AUTOSAR XML (schema 00044)
package /E40_Platform_System_SystemPackage/Components
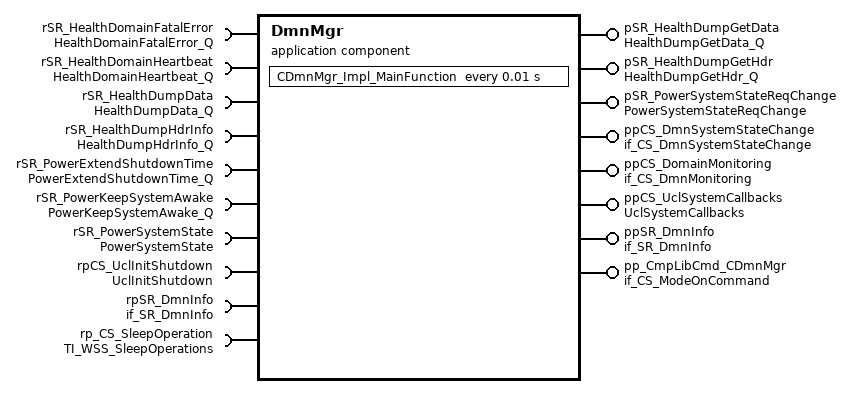
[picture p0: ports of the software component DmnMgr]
  application sw component type DmnMgr
    8 x provide port:
      pSR_HealthDumpGetData: queued-sender-com-spec=HealthDumpGetDataData, provided-interface=HealthDumpGetData_Q
      pSR_HealthDumpGetHdr: queued-sender-com-spec=HealthDumpGetHdrData, provided-interface=HealthDumpGetHdr_Q
      pSR_PowerSystemStateReqChange: nonqueued-sender-com-spec{data-element=PowerSystemStateReqChangeData, init-value=constant-reference=DmnMgrPowerSystemStateReqChangeDataValue0}, provided-interface=PowerSystemStateReqChange
      ppCS_DmnSystemStateChange: provided-interface=if_CS_DmnSystemStateChange
        provided-com-specs:
          operation=DmnSystemStateChangeReq, queue-length=1
          operation=DmnSystemStateChangeStatus, queue-length=1
      ppCS_DomainMonitoring: provided-com-specs=[{operation=StartDomainMonitoring, queue-length=1}, {operation=StopDomainMonitoring, queue-length=1}], provided-interface=if_CS_DmnMonitoring
      ppCS_UclSystemCallbacks: provided-com-specs=[{operation=ErrorNotification, queue-length=1}, {operation=LinkStatusChanged, queue-length=1}], provided-interface=UclSystemCallbacks
      ppSR_DmnInfo: nonqueued-sender-com-spec{data-element=SDmnStatus, init-value=constant-reference=DmnMgrSDmnStatusValue0}, provided-interface=if_SR_DmnInfo
      pp_CmpLibCmd_CDmnMgr: server-com-spec{operation=Impl_OnCommand, queue-length=1}, provided-interface=if_CS_ModeOnCommand
    10 x require port:
      rSR_HealthDomainFatalError: queued-receiver-com-spec{data-element=HealthDomainFatalErrorData, queue-length=2}, required-interface=HealthDomainFatalError_Q
      rSR_HealthDomainHeartbeat: queued-receiver-com-spec{data-element=HealthDomainHeartbeatData, queue-length=5}, required-interface=HealthDomainHeartbeat_Q
      rSR_HealthDumpData: queued-receiver-com-spec{data-element=HealthDumpDataData, queue-length=1}, required-interface=HealthDumpData_Q
      rSR_HealthDumpHdrInfo: queued-receiver-com-spec{data-element=HealthDumpHdrInfoData, queue-length=1}, required-interface=HealthDumpHdrInfo_Q
      rSR_PowerExtendShutdownTime: queued-receiver-com-spec{data-element=PowerExtendShutdownTimeData, queue-length=5}, required-interface=PowerExtendShutdownTime_Q
      rSR_PowerKeepSystemAwake: queued-receiver-com-spec{data-element=PowerKeepSystemAwakeData, queue-length=5}, required-interface=PowerKeepSystemAwake_Q
      rSR_PowerSystemState: nonqueued-receiver-com-spec{data-element=PowerSystemStateData, init-value=constant-reference=DmnMgrPowerSystemStateDataValue0}, required-interface=PowerSystemState
      rpCS_UclInitShutdown: required-com-specs=[Impl_Initialize, Impl_Shutdown], required-interface=UclInitShutdown
      rpSR_DmnInfo: nonqueued-receiver-com-spec{data-element=SDmnStatus, init-value=constant-reference=DmnMgrSDmnStatusValue0}, required-interface=if_SR_DmnInfo
      rp_CS_SleepOperation: required-com-specs=[CtrlWSS_CancelSleep, CtrlWSS_ReadytoSleep, CtrlWSS_RequestSleep], required-interface=TI_WSS_SleepOperations
    behavior IB_DmnMgr
      timing event TECDmnMgr_Impl_MainFunction: start-on-event=CDmnMgr_Impl_MainFunction, period=0.01
      5 x operation invoked event:
        OIE_pp_CmpLibCmd_CDmnMgr_CDmnMgr_Impl_OnCommandTrigByImpl_OnCommand: start-on-event=CDmnMgr_Impl_OnCommand, operation=pp_CmpLibCmd_CDmnMgr.Impl_OnCommand
        OIE_ppCS_DmnSystemStateChange_DmnMgr_DmnSystemStateChangeReqTrigByDmnSystemStateChangeReq: start-on-event=DmnMgr_DmnSystemStateChangeReq, operation=ppCS_DmnSystemStateChange.DmnSystemStateChangeReq
        OIE_ppCS_DmnSystemStateChange_DmnMgr_DmnSystemStateChangeStatusTrigByDmnSystemStateChangeStatus: start-on-event=DmnMgr_DmnSystemStateChangeStatus, operation=ppCS_DmnSystemStateChange.DmnSystemStateChangeStatus
        OIE_ppCS_UclSystemCallbacks_DmnMgr_ErrorNotificationTrigByErrorNotification: start-on-event=DmnMgr_ErrorNotification, operation=ppCS_UclSystemCallbacks.ErrorNotification
        OIE_ppCS_UclSystemCallbacks_DmnMgr_LinkStatusChangedTrigByLinkStatusChanged: start-on-event=DmnMgr_LinkStatusChanged, operation=ppCS_UclSystemCallbacks.LinkStatusChanged
      7 x data received event:
        DREDmnMgr_MonitorDmnExtendShutdownTimeTrigByPowerExtendShutdownTimeData: start-on-event=DmnMgr_MonitorDmnExtendShutdownTime, data=rSR_PowerExtendShutdownTime.PowerExtendShutdownTimeData
        DREDmnMgr_MonitorDmnHealthDumpDataTrigByHealthDumpDataData: start-on-event=DmnMgr_MonitorDmnHealthDumpData, data=rSR_HealthDumpData.HealthDumpDataData
        DREDmnMgr_MonitorDmnHealthDumpHdrInfoTrigByHealthDumpHdrInfoData: start-on-event=DmnMgr_MonitorDmnHealthDumpHdrInfo, data=rSR_HealthDumpHdrInfo.HealthDumpHdrInfoData
        DREDmnMgr_MonitorDmnHealthFatalErrorTrigByHealthDomainFatalErrorData: start-on-event=DmnMgr_MonitorDmnHealthFatalError, data=rSR_HealthDomainFatalError.HealthDomainFatalErrorData
        DREDmnMgr_MonitorDmnHeartBeatTrigByHealthDomainHeartbeatData: start-on-event=DmnMgr_MonitorDmnHeartBeat, data=rSR_HealthDomainHeartbeat.HealthDomainHeartbeatData
        DREDmnMgr_MonitorDmnKeepSystemAwakeTrigByPowerKeepSystemAwakeData: start-on-event=DmnMgr_MonitorDmnKeepSystemAwake, data=rSR_PowerKeepSystemAwake.PowerKeepSystemAwakeData
        DREDmnMgr_MonitorDmnPowerSystemStateTrigByPowerSystemStateData: start-on-event=DmnMgr_MonitorDmnPowerSystemState, data=rSR_PowerSystemState.PowerSystemStateData
      operation invoked event OIE_ppCS_DomainMonitoring_DmnMgr_StartDomainMonitoringTrigByStartDomainMonitoring: start-on-event=DmnMgr_StartDomainMonitoring, operation=ppCS_DomainMonitoring.StartDomainMonitoring
      operation invoked event OIE_ppCS_DomainMonitoring_DmnMgr_StopDomainMonitoringTrigByStopDomainMonitoring: start-on-event=DmnMgr_StopDomainMonitoring, operation=ppCS_DomainMonitoring.StopDomainMonitoring
      port-api-options:
        enable-take-address=false, indirect-api=false, port=pSR_HealthDumpGetData
        enable-take-address=false, indirect-api=false, port=pSR_HealthDumpGetHdr
        enable-take-address=false, indirect-api=false, port=pSR_PowerSystemStateReqChange
        enable-take-address=false, indirect-api=false, port=ppCS_DmnSystemStateChange
        enable-take-address=false, indirect-api=false, port=ppCS_DomainMonitoring
        enable-take-address=false, indirect-api=false, port=ppCS_UclSystemCallbacks
        enable-take-address=false, indirect-api=false, port=ppSR_DmnInfo
        enable-take-address=false, indirect-api=false, port=pp_CmpLibCmd_CDmnMgr
        enable-take-address=false, indirect-api=false, port=rSR_HealthDomainFatalError
        enable-take-address=false, indirect-api=false, port=rSR_HealthDomainHeartbeat
        enable-take-address=false, indirect-api=false, port=rSR_HealthDumpData
        enable-take-address=false, indirect-api=false, port=rSR_HealthDumpHdrInfo
        enable-take-address=false, indirect-api=false, port=rSR_PowerExtendShutdownTime
        enable-take-address=false, indirect-api=false, port=rSR_PowerKeepSystemAwake
        enable-take-address=false, indirect-api=false, port=rSR_PowerSystemState
        enable-take-address=false, indirect-api=false, port=rpCS_UclInitShutdown
        enable-take-address=false, indirect-api=false, port=rpSR_DmnInfo
        enable-take-address=false, indirect-api=false, port=rp_CS_SleepOperation
      15 x runnable, all with can-be-invoked-concurrently=true:
        CDmnMgr_Impl_MainFunction
          data-receive-point-by-arguments:
            8 x access:
              DRP_rSR_HealthDomainFatalError_HealthDomainFatalErrorData: accessed-variable=rSR_HealthDomainFatalError.HealthDomainFatalErrorData
              DRP_rSR_HealthDomainHeartbeat_HealthDomainHeartbeatData: accessed-variable=rSR_HealthDomainHeartbeat.HealthDomainHeartbeatData
              DRP_rSR_HealthDumpData_HealthDumpDataData: accessed-variable=rSR_HealthDumpData.HealthDumpDataData
              DRP_rSR_HealthDumpHdrInfo_HealthDumpHdrInfoData: accessed-variable=rSR_HealthDumpHdrInfo.HealthDumpHdrInfoData
              DRP_rSR_PowerExtendShutdownTime_PowerExtendShutdownTimeData: accessed-variable=rSR_PowerExtendShutdownTime.PowerExtendShutdownTimeData
              DRP_rSR_PowerKeepSystemAwake_PowerKeepSystemAwakeData: accessed-variable=rSR_PowerKeepSystemAwake.PowerKeepSystemAwakeData
              DRA_rSR_PowerSystemState_PowerSystemStateData: accessed-variable=rSR_PowerSystemState.PowerSystemStateData
              DRA_rpSR_DmnInfo_SDmnStatus: accessed-variable=rpSR_DmnInfo.SDmnStatus
          data-send-points:
            4 x access:
              DSP_pSR_HealthDumpGetData_HealthDumpGetDataData: accessed-variable=pSR_HealthDumpGetData.HealthDumpGetDataData
              DSP_pSR_HealthDumpGetHdr_HealthDumpGetHdrData: accessed-variable=pSR_HealthDumpGetHdr.HealthDumpGetHdrData
              DWA_pSR_PowerSystemStateReqChange_PowerSystemStateReqChangeData: accessed-variable=pSR_PowerSystemStateReqChange.PowerSystemStateReqChangeData
              DWA_ppSR_DmnInfo_SDmnStatus: accessed-variable=ppSR_DmnInfo.SDmnStatus
          5 x sync call:
            OA_rpCS_UclInitShutdown_Impl_Shutdown: operation=rpCS_UclInitShutdown.Impl_Shutdown
            OA_rpCS_UclInitShutdown_Impl_Initialize: operation=rpCS_UclInitShutdown.Impl_Initialize
            OA_rp_CS_SleepOperation_CtrlWSS_ReadytoSleep: operation=rp_CS_SleepOperation.CtrlWSS_ReadytoSleep
            OA_rp_CS_SleepOperation_CtrlWSS_RequestSleep: operation=rp_CS_SleepOperation.CtrlWSS_RequestSleep
            OA_rp_CS_SleepOperation_CtrlWSS_CancelSleep: operation=rp_CS_SleepOperation.CtrlWSS_CancelSleep
        CDmnMgr_Impl_OnCommand
        DmnMgr_DmnSystemStateChangeReq
        DmnMgr_DmnSystemStateChangeStatus
        DmnMgr_ErrorNotification
        DmnMgr_LinkStatusChanged
        DmnMgr_MonitorDmnExtendShutdownTime
        DmnMgr_MonitorDmnHealthDumpData
        DmnMgr_MonitorDmnHealthDumpHdrInfo
        DmnMgr_MonitorDmnHealthFatalError
        DmnMgr_MonitorDmnHeartBeat
        DmnMgr_MonitorDmnKeepSystemAwake
        DmnMgr_MonitorDmnPowerSystemState
        DmnMgr_StartDomainMonitoring
        DmnMgr_StopDomainMonitoring
  swc implementation IMPL_DmnMgr: behavior=IB_DmnMgr
